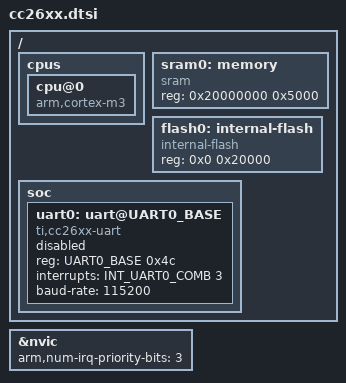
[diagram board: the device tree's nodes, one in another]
#include <arm/armv7-m.dtsi>
#include <inc/hw_memmap.h>
#include <inc/hw_ints.h>

/* Note: Zephyr uses exception numbers, vs the IRQ #s used by the CC3200 SDK */
/* which are offset by 16: */
#define EXP_UARTA0 (INT_UARTA0 - 16)
#define EXP_UARTA1 (INT_UARTA1 - 16)

/ {
	cpus {
		cpu@0 {
			compatible = "arm,cortex-m3";
		};
	};

	sram0: memory {
		compatible = "sram";
		reg = <0x20000000 0x5000>;
	};

	flash0: internal-flash {
		compatible = "internal-flash";
		reg = <0x0 0x20000>;
	};

	soc {
		uart0: uart@UART0_BASE {
			compatible = "ti,cc26xx-uart";
			reg = <UART0_BASE 0x4c>;
			interrupts = <INT_UART0_COMB 3>;
			baud-rate = <115200>;
			status = "disabled";
		};

	};
};

&nvic {
	arm,num-irq-priority-bits = <3>;
};
